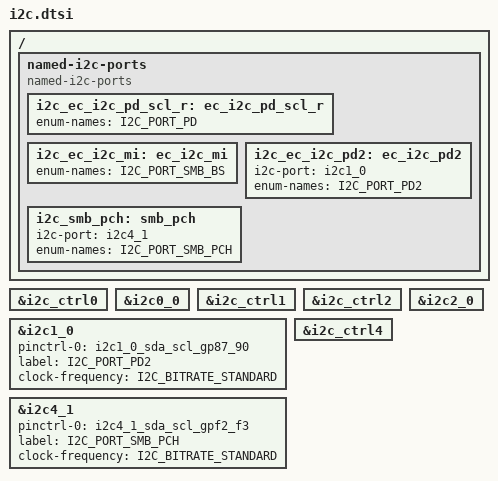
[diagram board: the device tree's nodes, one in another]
/* Copyright 2024 The ChromiumOS Authors
 * Use of this source code is governed by a BSD-style license that can be
 * found in the LICENSE file.
 */

/ {
	named-i2c-ports {
		compatible = "named-i2c-ports";

		i2c_ec_i2c_pd_scl_r: ec_i2c_pd_scl_r {
			enum-names = "I2C_PORT_PD";
		};
		i2c_ec_i2c_mi: ec_i2c_mi {
			enum-names = "I2C_PORT_SMB_BS";
		};
		i2c_ec_i2c_pd2: ec_i2c_pd2 {
			i2c-port = <&i2c1_0>;
			enum-names = "I2C_PORT_PD2";
		};
		i2c_smb_pch: smb_pch {
			i2c-port = <&i2c4_1>;
			enum-names = "I2C_PORT_SMB_PCH";
		};
	};
};

&i2c_ctrl0 {
	status = "okay";
};

pd_pow_i2c: &i2c0_0 {
};

&i2c_ctrl1 {
	status = "okay";
};

&i2c1_0 {
	status = "okay";
	pinctrl-0 = <&i2c1_0_sda_scl_gp87_90>;
	pinctrl-names = "default";

	label = "I2C_PORT_PD2";
	clock-frequency = <I2C_BITRATE_STANDARD>;
};

&i2c_ctrl2 {
	status = "okay";
};

charger_i2c: &i2c2_0 {
};

&i2c_ctrl4 {
	status = "okay";
};

&i2c4_1 {
	status = "okay";
	pinctrl-0 = <&i2c4_1_sda_scl_gpf2_f3>;
	pinctrl-names = "default";

	label = "I2C_PORT_SMB_PCH";
	clock-frequency = <I2C_BITRATE_STANDARD>;
};

#include "../../intelrvp/ptlrvp/i2c.dtsi"

/*
 * Using IT8801 MFD driver
 * These lines can be deleted after all PTL platforms support the MFD driver.
 * b/386325459
 */
/delete-node/ &kb_discrete;
